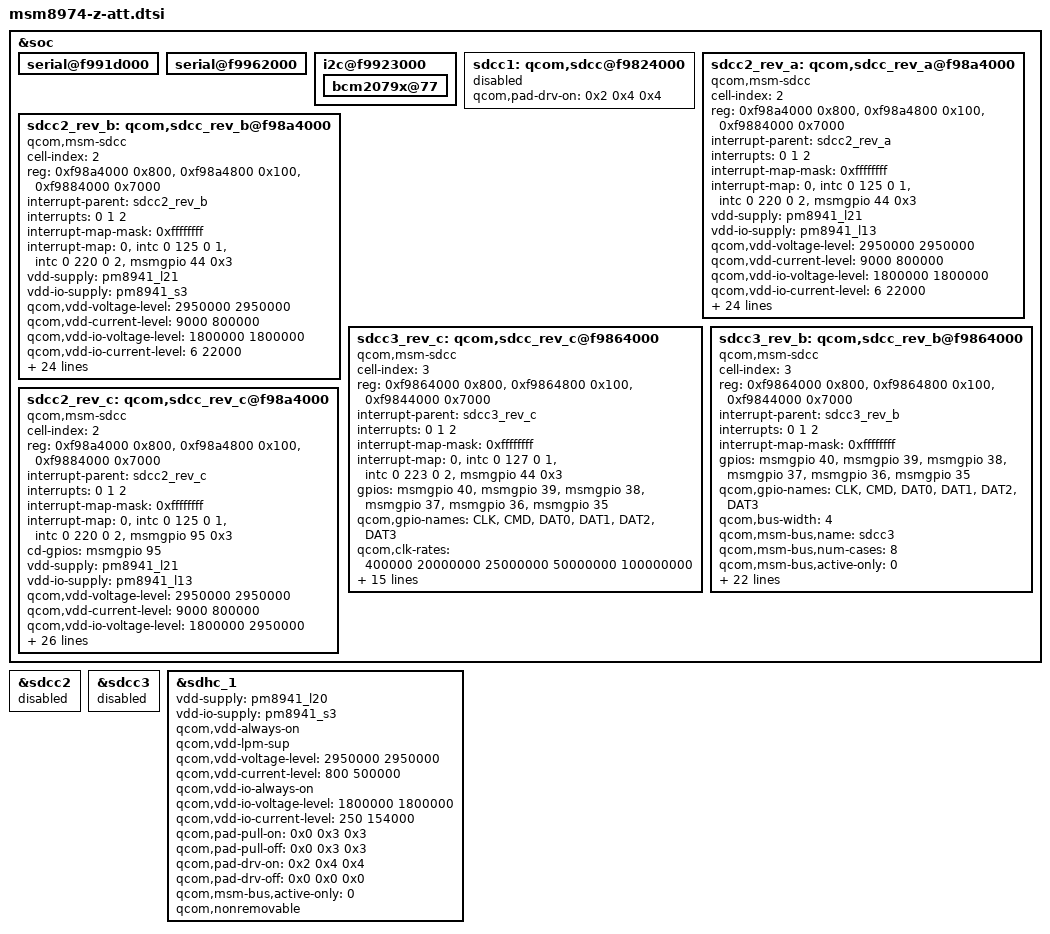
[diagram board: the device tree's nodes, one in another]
/* Copyright (c) 2012, Code Aurora Forum. All rights reserved.
 *
 * This program is free software; you can redistribute it and/or modify
 * it under the terms of the GNU General Public License version 2 and
 * only version 2 as published by the Free Software Foundation.
 *
 * This program is distributed in the hope that it will be useful,
 * but WITHOUT ANY WARRANTY; without even the implied warranty of
 * MERCHANTABILITY or FITNESS FOR A PARTICULAR PURPOSE.  See the
 * GNU General Public License for more details.
 */

/include/ "msm8974-z-att-panel.dtsi"
/include/ "msm8974-z-att-input.dtsi"
/include/ "msm8974-z-att-hdmi.dtsi"
/include/ "msm8974-z-att-usb.dtsi"
/include/ "msm8974-z-att-misc.dtsi"
/include/ "msm8974-z-att-pm.dtsi"
/include/ "msm8974-z-att-camera.dtsi"
/include/ "msm8974-z-att-nfc.dtsi" /* [NFC][wongab.jeon@lge.com], 2013-02-13, NFC Bring up */
/include/ "msm8974-z-att-sound.dtsi"

&soc {
	serial@f991d000 {
		status = "ok";
	};

	serial@f9962000 {
		status = "ok";
	};
	/*  LGE_CHANGE_E, [NFC][wongab.jeon@lge.com], 2013-02-13, NFC Bring up */
	
	
	/*  LGE_CHANGE_S, [NFC][wongab.jeon@lge.com], 2013-02-13, NFC Bring up */
	i2c@f9923000 {
		bcm2079x@77 {
			status = "ok";
		};
	};
	/*  LGE_CHANGE_E, [NFC][wongab.jeon@lge.com], 2013-02-13, NFC Bring up */

	sdcc1: qcom,sdcc@f9824000 {
		qcom,pad-drv-on = <0x2 0x4 0x4>; /* 16mA, 10mA, 10mA --> 6mA, 10mA, 10mA */
	};

	/* Below is SDCC2 */
	sdcc2_rev_a: qcom,sdcc_rev_a@f98a4000 {
		cell-index = <2>; /* SDC2 WLAN slot */
		compatible = "qcom,msm-sdcc";
		reg = <0xf98a4000 0x800>,
			<0xf98a4800 0x100>,
			<0xf9884000 0x7000>;
		reg-names = "core_mem", "dml_mem", "bam_mem";
		#address-cells = <0>;
		interrupt-parent = <&sdcc2_rev_a>;
		interrupts = <0 1 2>;
		#interrupt-cells = <1>;
		interrupt-map-mask = <0xffffffff>;
		interrupt-map = <0 &intc 0 125 0
				1 &intc 0 220 0
				2 &msmgpio 44 0x3>;
		interrupt-names = "core_irq", "bam_irq", "wlan_oob_irq";

		vdd-supply = <&pm8941_l21>;
		vdd-io-supply = <&pm8941_l13>;

		qcom,vdd-voltage-level = <2950000 2950000>;
		qcom,vdd-current-level = <9000 800000>;

		qcom,vdd-io-voltage-level = <1800000 1800000>;
		qcom,vdd-io-current-level = <6 22000>;

		qcom,pad-pull-on = <0x0 0x3 0x3>; /* no-pull, pull-up, pull-up */
		qcom,pad-pull-off = <0x0 0x3 0x3>; /* no-pull, pull-up, pull-up */
		qcom,pad-drv-on = <0x7 0x7 0x7>; /* 16mA, 16mA, 16mA */
		qcom,pad-drv-off = <0x0 0x0 0x0>; /* 2mA, 2mA, 2mA */

		qcom,clk-rates = <400000 20000000 25000000 50000000 100000000>;
		qcom,sup-voltages = <1800 2950>;
		qcom,bus-width = <4>;
		qcom,xpc;
		/* qcom,nonremovable; */
		qcom,bus-speed-mode = "SDR12", "SDR25", "SDR50";
		qcom,current-limit = <800>;

		qcom,msm-bus,name = "sdcc2";
		qcom,msm-bus,num-cases = <8>;
		qcom,msm-bus,active-only = <0>;
		qcom,msm-bus,num-paths = <1>;
		qcom,msm-bus,vectors-KBps = <81 512 0 0>, /* No vote */
				<81 512 1600 3200>,    /* 400 KB/s*/
				<81 512 80000 160000>, /* 20 MB/s */
				<81 512 100000 200000>, /* 25 MB/s */
				<81 512 200000 400000>, /* 50 MB/s */
				<81 512 400000 800000>, /* 100 MB/s */
				<81 512 800000 1600000>, /* 200 MB/s */
				<81 512 2048000 4096000>; /* Max. bandwidth */
		qcom,bus-bw-vectors-bps = <0 400000 20000000 25000000 50000000 100000000 200000000 4294967295>;
		qcom,dat1-mpm-int = <44>;
		revision = "...rev_a";
		status = "ok";
	};

	sdcc2_rev_b: qcom,sdcc_rev_b@f98a4000 {
		cell-index = <2>; /* SDC2 WLAN slot */
		compatible = "qcom,msm-sdcc";
		reg = <0xf98a4000 0x800>,
			<0xf98a4800 0x100>,
			<0xf9884000 0x7000>;
		reg-names = "core_mem", "dml_mem", "bam_mem";
		#address-cells = <0>;
		interrupt-parent = <&sdcc2_rev_b>;
		interrupts = <0 1 2>;
		#interrupt-cells = <1>;
		interrupt-map-mask = <0xffffffff>;
		interrupt-map = <0 &intc 0 125 0
				1 &intc 0 220 0
				2 &msmgpio 44 0x3>;
		interrupt-names = "core_irq", "bam_irq", "wlan_oob_irq";

		vdd-supply = <&pm8941_l21>;
		vdd-io-supply = <&pm8941_s3>;

		qcom,vdd-voltage-level = <2950000 2950000>;
		qcom,vdd-current-level = <9000 800000>;

		qcom,vdd-io-voltage-level = <1800000 1800000>;
		qcom,vdd-io-current-level = <6 22000>;

		qcom,pad-pull-on = <0x0 0x3 0x3>; /* no-pull, pull-up, pull-up */
		qcom,pad-pull-off = <0x0 0x3 0x3>; /* no-pull, pull-up, pull-up */
		qcom,pad-drv-on = <0x7 0x7 0x7>; /* 16mA, 16mA, 16mA */
		qcom,pad-drv-off = <0x0 0x0 0x0>; /* 2mA, 2mA, 2mA */

		qcom,clk-rates = <400000 20000000 25000000 50000000 100000000>;
		qcom,sup-voltages = <1800 2950>;
		qcom,bus-width = <4>;
		qcom,xpc;
		/* qcom,nonremovable; */
		qcom,bus-speed-mode = "SDR12", "SDR25", "SDR50";
		qcom,current-limit = <800>;

		qcom,msm-bus,name = "sdcc2";
		qcom,msm-bus,num-cases = <8>;
		qcom,msm-bus,active-only = <0>;
		qcom,msm-bus,num-paths = <1>;
		qcom,msm-bus,vectors-KBps = <81 512 0 0>, /* No vote */
				<81 512 1600 3200>,    /* 400 KB/s*/
				<81 512 80000 160000>, /* 20 MB/s */
				<81 512 100000 200000>, /* 25 MB/s */
				<81 512 200000 400000>, /* 50 MB/s */
				<81 512 400000 800000>, /* 100 MB/s */
				<81 512 800000 1600000>, /* 200 MB/s */
				<81 512 2048000 4096000>; /* Max. bandwidth */
		qcom,bus-bw-vectors-bps = <0 400000 20000000 25000000 50000000 100000000 200000000 4294967295>;
		qcom,dat1-mpm-int = <44>;
		revision = "rev_b";
		status = "ok";
	};

	sdcc3_rev_c: qcom,sdcc_rev_c@f9864000 {
		cell-index = <3>; /* SDC3 WLAN slot */
		compatible = "qcom,msm-sdcc";
		reg = <0xf9864000 0x800>,
			<0xf9864800 0x100>,
			<0xf9844000 0x7000>;
		reg-names = "core_mem", "dml_mem", "bam_mem";
		#address-cells = <0>;
		interrupt-parent = <&sdcc3_rev_c>;
		interrupts = <0 1 2>;
		#interrupt-cells = <1>;
		interrupt-map-mask = <0xffffffff>;
		interrupt-map = <0 &intc 0 127 0
				1 &intc 0 223 0
				2 &msmgpio 44 0x3>;
		interrupt-names = "core_irq", "bam_irq", "wlan_oob_irq";

		gpios = <&msmgpio 40 0>, /* CLK */
			<&msmgpio 39 0>, /* CMD */
			<&msmgpio 38 0>, /* DATA0 */
			<&msmgpio 37 0>, /* DATA1 */
			<&msmgpio 36 0>, /* DATA2 */
			<&msmgpio 35 0>; /* DATA3 */
		qcom,gpio-names = "CLK", "CMD", "DAT0", "DAT1", "DAT2", "DAT3";

		qcom,clk-rates = <400000 20000000 25000000 50000000 100000000>;
		qcom,sup-voltages = <1800 2950>;
		qcom,bus-width = <4>;
		qcom,bus-speed-mode = "SDR12", "SDR25", "SDR50";

		qcom,msm-bus,name = "sdcc3";
		qcom,msm-bus,num-cases = <8>;
		qcom,msm-bus,active-only = <0>;
		qcom,msm-bus,num-paths = <1>;
		qcom,msm-bus,vectors-KBps = <79 512 0 0>, /* No vote */
				<79 512 1600 3200>,    /* 400 KB/s*/
				<79 512 80000 160000>, /* 20 MB/s */
				<79 512 100000 200000>, /* 25 MB/s */
				<79 512 200000 400000>, /* 50 MB/s */
				<79 512 400000 800000>, /* 100 MB/s */
				<79 512 800000 1600000>, /* 200 MB/s */
				<79 512 2048000 4096000>; /* Max. bandwidth */
		qcom,bus-bw-vectors-bps = <0 400000 20000000 25000000 50000000 100000000 200000000 4294967295>;
		revision = "rev_c...";
		status = "ok";
	};

	sdcc3_rev_b: qcom,sdcc_rev_b@f9864000 {
		cell-index = <3>; /* SDC3 SD-card slot */
		compatible = "qcom,msm-sdcc";
		reg = <0xf9864000 0x800>,
			<0xf9864800 0x100>,
			<0xf9844000 0x7000>;
		reg-names = "core_mem", "dml_mem", "bam_mem";
		#address-cells = <0>;
		interrupt-parent = <&sdcc3_rev_b>;
		interrupts = <0 1 2>;
		#interrupt-cells = <1>;
		interrupt-map-mask = <0xffffffff>;

		gpios = <&msmgpio 40 0>, /* CLK */
			<&msmgpio 39 0>, /* CMD */
			<&msmgpio 38 0>, /* DATA0 */
			<&msmgpio 37 0>, /* DATA1 */
			<&msmgpio 36 0>, /* DATA2 */
			<&msmgpio 35 0>; /* DATA3 */
		qcom,gpio-names = "CLK", "CMD", "DAT0", "DAT1", "DAT2", "DAT3";

		qcom,bus-width = <4>;

		qcom,msm-bus,name = "sdcc3";
		qcom,msm-bus,num-cases = <8>;
		qcom,msm-bus,active-only = <0>;
		qcom,msm-bus,num-paths = <1>;
		qcom,msm-bus,vectors-KBps = <79 512 0 0>, /* No vote */
				<79 512 1600 3200>,    /* 400 KB/s*/
				<79 512 80000 160000>, /* 20 MB/s */
				<79 512 100000 200000>, /* 25 MB/s */
				<79 512 200000 400000>, /* 50 MB/s */
				<79 512 400000 800000>, /* 100 MB/s */
				<79 512 800000 1600000>, /* 200 MB/s */
				<79 512 2048000 4096000>; /* Max. bandwidth */
		qcom,bus-bw-vectors-bps = <0 400000 20000000 25000000 50000000 100000000 200000000 4294967295>;

		/* Below is added by G2-FS */
		vdd-supply = <&pm8941_l21>;
		vdd-io-supply = <&pm8941_l13>;
		qcom,vdd-voltage-level = <2950000 2950000>;
		qcom,vdd-current-level = <9000 800000>;
		qcom,vdd-io-voltage-level = <1800000 2950000>;
		qcom,vdd-io-current-level = <6 22000>;

		interrupt-map = <0 &intc 0 127 0
				1 &intc 0 223 0
				2 &msmgpio 95 0x3>;
		interrupt-names = "core_irq", "bam_irq", "status_irq";
		cd-gpios = <&msmgpio 95 0x0>;

		qcom,clk-rates = <400000 20000000 25000000 50000000>;
		qcom,sup-voltages = <2950 2950>;
		qcom,bus-speed-mode = "SDR12", "SDR25", "DDR50";
		revision = "rev_b";
		status = "ok";
	};

	sdcc2_rev_c: qcom,sdcc_rev_c@f98a4000 {
		cell-index = <2>; /* SDC2 SD card slot */
		compatible = "qcom,msm-sdcc";
		reg = <0xf98a4000 0x800>,
			  <0xf98a4800 0x100>,
			  <0xf9884000 0x7000>;
		reg-names = "core_mem", "dml_mem", "bam_mem";

		#address-cells = <0>;
		interrupt-parent = <&sdcc2_rev_c>;
		interrupts = <0 1 2>;
		#interrupt-cells = <1>;
		interrupt-map-mask = <0xffffffff>;
		interrupt-map = <0 &intc 0 125 0
						1 &intc 0 220 0
						2 &msmgpio 95 0x3>;
		interrupt-names = "core_irq", "bam_irq", "status_irq";
		cd-gpios = <&msmgpio 95 0x0>; /* 1:Low-Active, 0:High-Active */

		vdd-supply = <&pm8941_l21>;
		vdd-io-supply = <&pm8941_l13>;

		qcom,vdd-voltage-level = <2950000 2950000>;
		qcom,vdd-current-level = <9000 800000>;

		qcom,vdd-io-voltage-level = <1800000 2950000>;
		qcom,vdd-io-current-level = <6 22000>;

		qcom,pad-pull-on = <0x0 0x3 0x3>; /* no-pull, pull-up, pull-up */
		qcom,pad-pull-off = <0x0 0x3 0x3>; /* no-pull, pull-up, pull-up */
		qcom,pad-drv-on = <0x7 0x4 0x4>; /* 16mA, 10mA, 10mA */
		qcom,pad-drv-off = <0x0 0x0 0x0>; /* 2mA, 2mA, 2mA */

		qcom,clk-rates = <400000 20000000 25000000 50000000 100000000 200000000>;
		qcom,sup-voltages = <2950 2950>;
		qcom,bus-width = <4>;
		qcom,xpc;
		qcom,bus-speed-mode = "SDR12", "SDR25", "SDR50", "DDR50", "SDR104";
		qcom,current-limit = <800>;

		qcom,msm-bus,name = "sdcc2";
		qcom,msm-bus,num-cases = <8>;
		qcom,msm-bus,active-only = <0>;
		qcom,msm-bus,num-paths = <1>;
		qcom,msm-bus,vectors-KBps = <81 512 0 0>, /* No vote */
				<81 512 1600 3200>,    /* 400 KB/s*/
				<81 512 80000 160000>, /* 20 MB/s */
				<81 512 100000 200000>, /* 25 MB/s */
				<81 512 200000 400000>, /* 50 MB/s */
				<81 512 400000 800000>, /* 100 MB/s */
				<81 512 800000 1600000>, /* 200 MB/s */
				<81 512 2048000 4096000>; /* Max. bandwidth */
		qcom,bus-bw-vectors-bps = <0 400000 20000000 25000000 50000000 100000000 200000000 4294967295>;
		qcom,dat1-mpm-int = <44>;
		revision = "rev_c...";
		status = "ok";
	};
};

&sdcc1 {
	status = "disable";
};

&sdcc2 {
	status = "disable";
};

&sdcc3 {
	status = "disable";
};

/* referenced from msm8974-cdp.dtsi */
&sdhc_1 {
	vdd-supply = <&pm8941_l20>;
	vdd-io-supply = <&pm8941_s3>;

	qcom,vdd-always-on;
	qcom,vdd-lpm-sup;
	qcom,vdd-voltage-level = <2950000 2950000>;
	qcom,vdd-current-level = <800 500000>;

	qcom,vdd-io-always-on;
	qcom,vdd-io-voltage-level = <1800000 1800000>;
	qcom,vdd-io-current-level = <250 154000>;

	qcom,pad-pull-on = <0x0 0x3 0x3>; /* no-pull, pull-up, pull-up */
	qcom,pad-pull-off = <0x0 0x3 0x3>; /* no-pull, pull-up, pull-up */
	qcom,pad-drv-on = <0x4 0x4 0x4>; /* 10mA, 10mA, 10mA */
	qcom,pad-drv-off = <0x0 0x0 0x0>; /* 2mA, 2mA, 2mA */

	qcom,msm-bus,active-only = <0>;
	qcom,nonremovable;
	status = "ok";
};

/* modify for Z-schematic */
&sdhc_1 {
	qcom,pad-drv-on = <0x2 0x4 0x4>; /* 10mA, 10mA, 10mA */
};
